# ATmega2564RFR2 register map
Vendor: Atmel; File version: 1.0
CPU: other r0p0, little endian, no MPU, no FPU, 4 interrupt priority bits
Registers are 8-bit, read-write, reset 0x0 unless marked. A register's access mark holds for its fields unless they carry their own. Offsets are from the block's base; [hi:lo] are bit positions; 'fields as' and 'values as' point back to an identical list.

## SPI — Serial Peripheral Interface
Base 0x0000004C
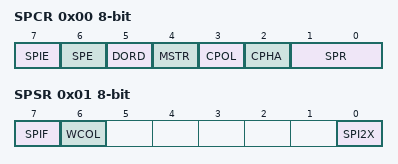
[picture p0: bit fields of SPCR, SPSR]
0x00 SPCR — SPI Control Register
  [7] SPIE — SPI Interrupt Enable
  [6] SPE — SPI Enable
  [5] DORD — Data Order
  [4] MSTR — Master/Slave Select
  [3] CPOL — Clock polarity
    0=Rising (Leading Edge), Falling (Trailing Edge); 1=Falling (Leading Egde), Rising (Trailing Edge)
  [2] CPHA — Clock Phase
    0=Sample (Leading Edge), Setup (Trailing Edge); 1=Setup (Leading Edge), Sample (Trailing Edge)
  [1:0] SPR — SPI Clock Rate Select 1 and 0
    0=fosc/4 / fosc/2 (SPI2X=0/1); 1=fosc/16 / fosc/8 (SPI2X=0/1); 2=fosc/64 / fosc/32 (SPI2X=0/1); 3=fosc/128 / fosc/64 (SPI2X=0/1)
0x01 SPSR — SPI Status Register
  [7] SPIF — SPI Interrupt Flag
  [6] WCOL — Write Collision Flag
  [0] SPI2X — Double SPI Speed Bit
0x02 SPDR — SPI Data Register

## TC0 — Timer/Counter, 8-bit
Base 0x00000035
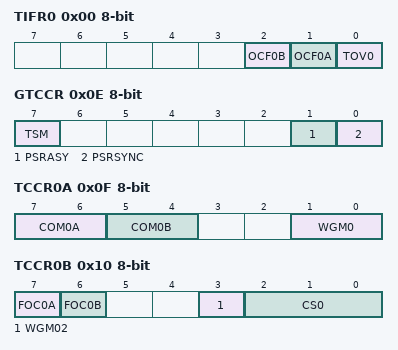
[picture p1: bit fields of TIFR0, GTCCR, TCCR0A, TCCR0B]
0x00 TIFR0 — Timer/Counter0 Interrupt Flag Register
  [2] OCF0B — Timer/Counter0 Output Compare B Match Flag
  [1] OCF0A — Timer/Counter0 Output Compare A Match Flag
  [0] TOV0 — Timer/Counter0 Overflow Flag
0x0E GTCCR — General Timer/Counter Control Register
  [7] TSM — Timer/Counter Synchronization Mode
  [1] PSRASY — Prescaler Reset Timer/Counter2
  [0] PSRSYNC — Prescaler Reset for Synchronous Timer/Counters
0x0F TCCR0A — Timer/Counter0 Control Register A
  [7:6] COM0A — Compare Match Output A Mode
    0=Normal port operation, OC0A disconnected; 1=Toggle OC0A on Compare Match; 2=Clear OC0A on Compare Match; 3=Set OC0A on Compare Match
  [5:4] COM0B — Compare Match Output B Mode
    0=Normal port operation, OC0B disconnected; 1=Toggle OC0B on Compare Match; 2=Clear OC0B on Compare Match; 3=Set OC0B on Compare Match
  [1:0] WGM0 — Waveform Generation Mode
    0=Normal mode of operation; 1=PWM, phase correct, TOP=0xFF; 2=CTC, TOP = OCRA; 3=Fast PWM, TOP=0xFF
0x10 TCCR0B — Timer/Counter0 Control Register B
  [7] FOC0A — Force Output Compare A
  [6] FOC0B — Force Output Compare B
  [3] WGM02
  [2:0] CS0 — Clock Select
    0=No clock source (Timer/Counter0 stopped); 1=clk_IO/1 (no prescaling); 2=clk_IO/8 (from prescaler); 3=clk_IO/64 (from prescaler); 4=clk_IO/256 (from prescaler); 5=clk_IO/1024 (from prescaler); 6=External clock source on T0 pin, clock on falling edge; 7=External clock source on T0 pin, clock on rising edge
0x11 TCNT0 — Timer/Counter0 Register
0x12 OCR0A — Timer/Counter0 Output Compare Register
0x13 OCR0B — Timer/Counter0 Output Compare Register B
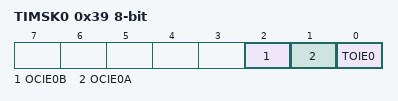
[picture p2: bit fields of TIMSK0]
0x39 TIMSK0 — Timer/Counter0 Interrupt Mask Register
  [2] OCIE0B — Timer/Counter0 Output Compare Match B Interrupt Enable
  [1] OCIE0A — Timer/Counter0 Output Compare Match A Interrupt Enable
  [0] TOIE0 — Timer/Counter0 Overflow Interrupt Enable

## TC1 — Timer/Counter, 16-bit
Base 0x00000036
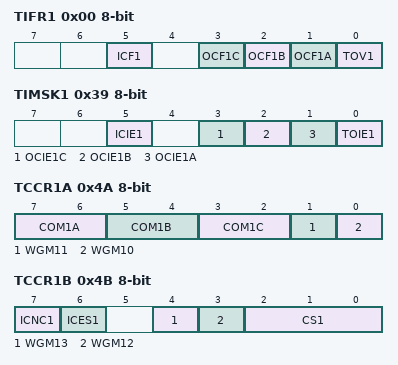
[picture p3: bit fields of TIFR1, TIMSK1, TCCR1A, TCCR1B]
0x00 TIFR1 — Timer/Counter1 Interrupt Flag Register
  [5] ICF1 — Timer/Counter1 Input Capture Flag
  [3] OCF1C — Timer/Counter1 Output Compare C Match Flag
  [2] OCF1B — Timer/Counter1 Output Compare B Match Flag
  [1] OCF1A — Timer/Counter1 Output Compare A Match Flag
  [0] TOV1 — Timer/Counter1 Overflow Flag
0x39 TIMSK1 — Timer/Counter1 Interrupt Mask Register
  [5] ICIE1 — Timer/Counter1 Input Capture Interrupt Enable
  [3] OCIE1C — Timer/Counter1 Output Compare C Match Interrupt Enable
  [2] OCIE1B — Timer/Counter1 Output Compare B Match Interrupt Enable
  [1] OCIE1A — Timer/Counter1 Output Compare A Match Interrupt Enable
  [0] TOIE1 — Timer/Counter1 Overflow Interrupt Enable
0x4A TCCR1A — Timer/Counter1 Control Register A
  [7:6] COM1A — Compare Output Mode for Channel A
    0=Normal port operation, OCnA/OCnB/OCnC disconnected; 1=Toggle OCnA/OCnB/OCnC on Compare Match; 2=Clear OCnA/OCnB/OCnC on Compare Match (set output to low level); 3=Set OCnA/OCnB/OCnC on Compare Match (set output to high level)
  [5:4] COM1B — Compare Output Mode for Channel B
    values as COM1A
  [3:2] COM1C — Compare Output Mode for Channel C
    values as COM1A
  [1] WGM11 — Waveform Generation Mode
  [0] WGM10 — Waveform Generation Mode
0x4B TCCR1B — Timer/Counter1 Control Register B
  [7] ICNC1 — Input Capture 1 Noise Canceller
  [6] ICES1 — Input Capture 1 Edge Select
  [4] WGM13 — Waveform Generation Mode
  [3] WGM12 — Waveform Generation Mode
  [2:0] CS1 — Clock Select
    0=No clock source (Timer/Counter stopped); 1=clk_IO/1 (no prescaling); 2=clk_IO/8 (from prescaler); 3=clk_IO/64 (from prescaler); 4=clk_IO/256 (from prescaler); 5=clk_IO/1024 (from prescaler); 6=External clock source on Tn pin, clock on falling edge; 7=External clock source on Tn pin, clock on rising edge
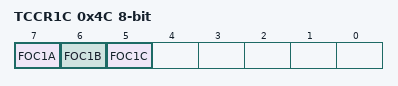
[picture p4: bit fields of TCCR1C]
0x4C TCCR1C — Timer/Counter1 Control Register C
  [7] FOC1A — Force Output Compare for Channel A
  [6] FOC1B — Force Output Compare for Channel B
  [5] FOC1C — Force Output Compare for Channel C
0x4E TCNT1 16-bit (reset mask 0xFF) — Timer/Counter1 Bytes
0x50 ICR1 16-bit (reset mask 0xFF) — Timer/Counter1 Input Capture Register Bytes
0x52 OCR1A 16-bit (reset mask 0xFF) — Timer/Counter1 Output Compare Register A Bytes
0x54 OCR1B 16-bit (reset mask 0xFF) — Timer/Counter1 Output Compare Register B Bytes
0x56 OCR1C 16-bit (reset mask 0xFF) — Timer/Counter1 Output Compare Register C Bytes
